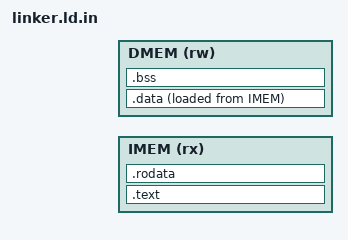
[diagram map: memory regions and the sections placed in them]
/* Generated by project_config.py; do not edit.
 * Configuration digest: @CONFIG_DIGEST@
 */
OUTPUT_ARCH(riscv)
ENTRY(_start)

MEMORY
{
  IMEM (rx)  : ORIGIN = @IMEM_ORIGIN@, LENGTH = @IMEM_LENGTH@
  DMEM (rw)  : ORIGIN = @DMEM_ORIGIN@, LENGTH = @DMEM_LENGTH@
}

SECTIONS
{
  .text :
  {
    KEEP(*(.text.start))
    *(.text .text.*)
  } > IMEM

  .rodata :
  {
    *(.rodata .rodata.*)
    *(.srodata .srodata.*)
    *(.eh_frame .eh_frame.*)
  } > IMEM

  .data :
  {
    . = ALIGN(4);
    __data_start = .;
    *(.data .data.*)
    *(.sdata .sdata.*)
    . = ALIGN(4);
    __data_end = .;
  } > DMEM AT > IMEM
  __data_load_start = LOADADDR(.data);
  PROVIDE(__global_pointer$ = __data_start + 0x800);

  .bss (NOLOAD) :
  {
    . = ALIGN(4);
    __bss_start = .;
    *(.bss .bss.*)
    *(.sbss .sbss.*)
    *(COMMON)
    . = ALIGN(4);
    __bss_end = .;
  } > DMEM

  . = ALIGN(16);
  __heap_start = .;
  __stack_top = (ORIGIN(DMEM) + LENGTH(DMEM)) & ~15;
  __heap_end = __stack_top;
  ASSERT(__heap_start <= __stack_top, "DMEM overflow")

  /DISCARD/ :
  {
    *(.comment)
    *(.note .note.*)
  }
}
